# AE722F80F55D5AS_CM55_HP_View register map
Vendor: Alif Semiconductor; Series: E7; File version: 1.0
CPU: CM55 r1p0, selectable endian, MPU, FPU, double-precision FPU, DSP, VTOR, 8 interrupt priority bits, 1 SAU regions
Registers are 32-bit, read-write, reset 0x0 unless marked. A register's access mark holds for its fields unless they carry their own. Offsets are from the block's base; [hi:lo] are bit positions.

## M55HP_CFG
Base 0x400F0000
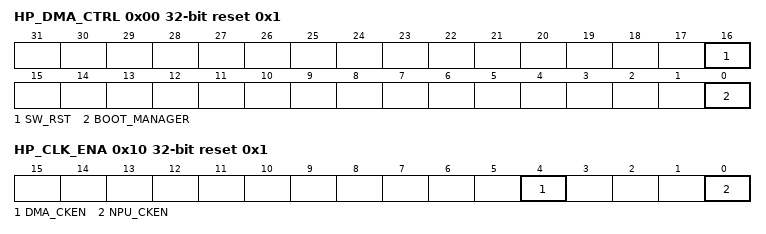
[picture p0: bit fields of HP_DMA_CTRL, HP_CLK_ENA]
0x00 HP_DMA_CTRL reset 0x1 — DMA1 Boot Control Register
  [16] SW_RST wo — Software reset for DMA1
    0=No reset; 1=Reset DMA1. This bit is self-cleared.
  [0] BOOT_MANAGER — When DMA1 exits from reset, this bit controls the security state of the DMA manager thread
    0=Assigns DMA manager to the secure state; 1=Assigns DMA manager to the non-secure state
0x04 HP_DMA_IRQ reset 0xFFFFFFFF — DMA1 Boot IRQ Non-Secure Register
  [31:0] BOOT_IRQ — Controls the security state of an event-interrupt resource, when DMA1 exits from reset
    0=DMA1 assigns event x or IRQ[x] to the secure state; 1=DMA1 assigns event x or IRQ[x] to the non-secure state
0x08 HP_DMA_PERIPH reset 0xFFFFFFFF — DMA1 Boot Peripheral Non-Secure Register
  [31:0] BOOT_PERIPH — Controls the security state of a peripheral request interface, when DMA1 exits from reset
    0=DMA1 assigns peripheral request interface x to the secure state; 1=DMA1 assigns peripheral request interface x to the non-secure state
0x0C HP_DMA_SEL — DMA1 Select Register
  [31:24] FLT_ENA — This field provides glitch filtering for the GPIO9_[7-0] signals that are mapped to DMA1 inputs [31-24] DMA1 (M55-HP) Requests Mapping). For each bit:
    0=Disable glitch-filter for GPIO input; 1=Enable glitch-filter for GPIO input
0x10 HP_CLK_ENA reset 0x1 — Peripheral Clock Enable Register
  [4] DMA_CKEN — Enable clock for DMA1 and EVTRTR1
    0=Disable clock; 1=Enable clock
  [0] NPU_CKEN — Enable clock for NPU-HP Note: When this bit is 0x1, the clock is automatically controlled. When this bit is 0x0, the clock is forcibly disabled, overriding the automatic control. Forcing this clock off can block RTSS-HP power domain state transitions or resets and does not save more power than the automatic gating. Therefore, this bit should remain 0x1 in normal operation. The control exists for test and debug purposes only.
    0=Disable clock; 1=Enable clock (automatic gating)

## WDT_HP_CTRL
Base 0x40100000
Same registers: WDT_HP_REFRESH 0x40101000
0x00 WDT_WDOGLOAD reset 0xFFFFFFFF — Watchdog Load Register
  [31:0] WDOGLOAD — When this bit field is written, the count is immediately restarted from the new value. The minimum valid value for this field is 0x1.
0x04 WDT_WDOGVALUE ro reset 0xFFFFFFFF — Watchdog Value Register
  [31:0] WDOGVALUE — This bit field gives the current value of the decrementing counter.
0x08 WDT_WDOGCONTROL — Watchdog Control Register
  [0] INTEN — Enables the interrupt event, WDT_IRQ. Reloads the counter from the value in WDT_WDOGLOAD register when the interrupt is enabled, afterpreviously being disabled.
    0=The counter and the interrupt are disabled; 1=The counter and the interrupt are enabled
0x0C WDT_WDOGINTCLR wo reset not defined — Watchdog Clear Interrupt Register
  [31:0] WDOGINTCLR — A write of any value clears the watchdog interrupt, and reloads the counter from the value in WDT_WDOGLOAD register.
0x10 WDT_WDOGRIS ro — Watchdog Raw Interrupt Status Register
  [0] RAW_WATCHDOG_INTERRUPT — Enables the raw interrupt status from the counter. This value is AND-ed with the value of WDT_WDOGCONTROL[INTEN] bit to create the masked interrupt.
0x14 WDT_WDOGMIS ro — Watchdog Interrupt Status Register
  [0] WATCHDOG_INTERRUPT — Enables the masked interrupt status from the counter. This value is the logical AND of the raw interrupt status with the WDT_WDOGCONTROL[INTEN] bit, and isthe value of the WDT_IRQ.
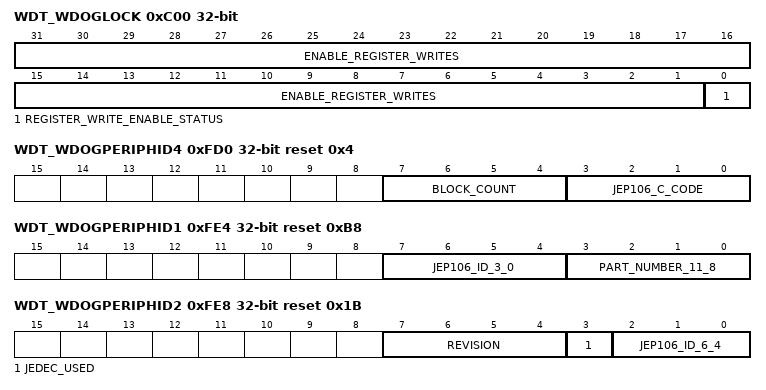
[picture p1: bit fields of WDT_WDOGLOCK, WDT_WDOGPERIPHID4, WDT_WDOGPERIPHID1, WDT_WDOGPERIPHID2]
0xC00 WDT_WDOGLOCK — Watchdog Lock Register
  [31:1] ENABLE_REGISTER_WRITES — Enable write access to all other registers by writing 0x1ACC_E551. Disable write access by writing any other value.
  [0] REGISTER_WRITE_ENABLE_STATUS — Write access status:
    0=Write access to all other registers is enabled; 1=Write access to all other registers is disabled
0xFD0 WDT_WDOGPERIPHID4 ro reset 0x4 — Peripheral ID Register 4
  [7:4] BLOCK_COUNT
  [3:0] JEP106_C_CODE — JEP106 continuation code value
0xFE0 WDT_WDOGPERIPHID0 ro reset 0x24 — Peripheral ID Register 0
  [7:0] PART_NUMBER_7_0 — Part number
0xFE4 WDT_WDOGPERIPHID1 ro reset 0xB8 — Peripheral ID Register 1
  [7:4] JEP106_ID_3_0 — JEP106 identity code [3:0]
  [3:0] PART_NUMBER_11_8 — Part number
0xFE8 WDT_WDOGPERIPHID2 ro reset 0x1B — Peripheral ID Register 2
  [7:4] REVISION — Revision of the TZC-400
  [3] JEDEC_USED — Indicates that the TZC-400 uses a manufacturer identity code allocated by JEDEC according to JEP106.
  [2:0] JEP106_ID_6_4 — JEP106 identity code [6:4]
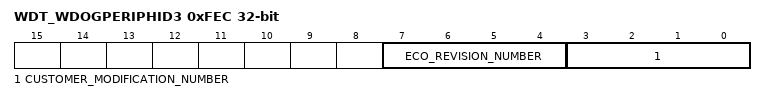
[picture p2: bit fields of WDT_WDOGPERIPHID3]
0xFEC WDT_WDOGPERIPHID3 ro — Peripheral ID Register 3
  [7:4] ECO_REVISION_NUMBER, [3:0] CUSTOMER_MODIFICATION_NUMBER
0xFF0 WDT_WDOGPCELLID0 ro reset 0xD — Component ID Register 0
  [7:0] COMPONENT_ID_0
0xFF4 WDT_WDOGPCELLID1 ro reset 0xF0 — Component ID Register 1
  [7:0] COMPONENT_ID_1
0xFF8 WDT_WDOGPCELLID2 ro reset 0x5 — Component ID Register 2
  [7:0] COMPONENT_ID_2
0xFFC WDT_WDOGPCELLID3 ro reset 0xB1 — Component ID Register 3
  [7:0] COMPONENT_ID_3
